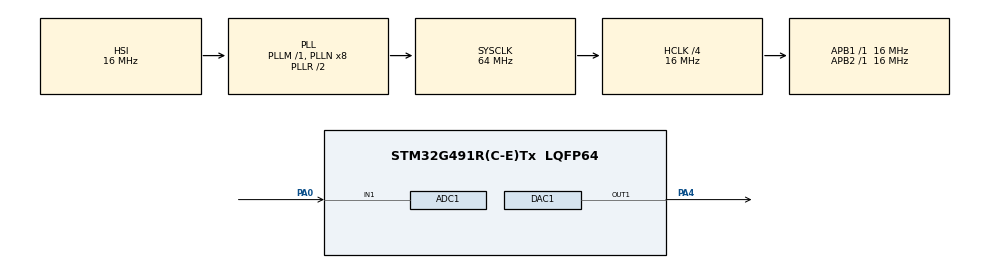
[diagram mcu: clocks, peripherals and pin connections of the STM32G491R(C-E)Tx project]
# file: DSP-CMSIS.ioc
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ADC1.Channel-0\#ChannelRegularConversion=ADC_CHANNEL_1
ADC1.NbrOfConversionFlag=1
ADC1.OffsetNumber-0\#ChannelRegularConversion=ADC_OFFSET_NONE
ADC1.Rank-0\#ChannelRegularConversion=1
ADC1.SamplingTime-0\#ChannelRegularConversion=ADC_SAMPLETIME_2CYCLES_5
ADC1.master=1
Mcu.Family=STM32G4
Mcu.Name=STM32G491R(C-E)Tx
Mcu.Package=LQFP64
NUCLEO-G491RE.BUTTON=1
NUCLEO-G491RE.LD2=true
NUCLEO-G491RE.VCP=true
NVIC.ADC1_2_IRQn=true\:0\:0\:false\:false\:true\:true\:true\:true
NVIC.EXTI15_10_IRQn=true\:0\:0\:false\:false\:true\:false\:true\:true
NVIC.PriorityGroup=NVIC_PRIORITYGROUP_4
NVIC.TIM2_IRQn=true\:0\:0\:false\:false\:true\:true\:true\:true
NVIC.TIM6_DAC_IRQn=true\:0\:0\:false\:false\:true\:true\:true\:true
PA0.Mode=IN1-Single-Ended
PA0.Signal=ADC1_IN1
PA13.GPIO_Label=T_SWDIO
PA13.Mode=Serial_Wire
PA13.Signal=SYS_JTMS-SWDIO
PA14.GPIO_Label=T_SWCLK
PA14.Mode=Serial_Wire
PA14.Signal=SYS_JTCK-SWCLK
PA2.Signal=LPUART1_TX
PA3.Signal=LPUART1_RX
PA4.Signal=COMP_DAC11_group
PB3.GPIO_Label=T_SWO
PB3.Signal=SYS_JTDO-SWO
PC14-OSC32_IN.GPIO_Label=RCC_OSC32_IN
PC14-OSC32_IN.Signal=RCC_OSC32_IN
PC15-OSC32_OUT.GPIO_Label=RCC_OSC32_OUT
PC15-OSC32_OUT.Signal=RCC_OSC32_OUT
PF0-OSC_IN.GPIO_Label=RCC_OSC_IN
PF0-OSC_IN.Signal=RCC_OSC_IN
PF1-OSC_OUT.GPIO_Label=RCC_OSC_OUT
PF1-OSC_OUT.Signal=RCC_OSC_OUT
ProjectManager.HeapSize=0x200
ProjectManager.StackSize=0x400
ProjectManager.TargetToolchain=STM32CubeIDE
RCC.ADC12Freq_Value=64000000
RCC.ADC345Freq_Value=64000000
RCC.AHBCLKDivider=RCC_SYSCLK_DIV4
RCC.AHBFreq_Value=16000000
RCC.APB1Freq_Value=16000000
RCC.APB1TimFreq_Value=16000000
RCC.APB2Freq_Value=16000000
RCC.APB2TimFreq_Value=16000000
RCC.CortexFreq_Value=16000000
RCC.EXTERNAL_CLOCK_VALUE=12288000
RCC.HCLKFreq_Value=16000000
RCC.HSE_VALUE=24000000
RCC.HSI48_VALUE=48000000
RCC.HSI_VALUE=16000000
RCC.LSE_VALUE=32768
RCC.RTCClockSelection=RCC_RTCCLKSOURCE_LSE
RCC.SYSCLKFreq_VALUE=64000000
RCC.SYSCLKSource=RCC_SYSCLKSOURCE_PLLCLK
RCC.USBFreq_Value=48000000
RCC.VCOOutputFreq_Value=128000000
SH.COMP_DAC11_group.0=DAC1_OUT1,DAC_OUT1
TIM2.PeriodNoDither=1
TIM2.Prescaler=999
VP_NUCLEO-G491RE_VS_BSP_COMMON.Mode=COMMON
VP_SYS_VS_DBSignals.Mode=DisableDeadBatterySignals
VP_TIM2_VS_ClockSourceINT.Mode=Internal
board=NUCLEO-G491RE

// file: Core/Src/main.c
/* USER CODE BEGIN Header */
/**
 ******************************************************************************
 * @file           : main.c
 * @brief          : Main program body
 ******************************************************************************
 * @attention
 *
 * Copyright (c) 2026 STMicroelectronics.
 * All rights reserved.
 *
 * This software is licensed under terms that can be found in the LICENSE file
 * in the root directory of this software component.
 * If no LICENSE file comes with this software, it is provided AS-IS.
 *
 ******************************************************************************
 */

/*
 *
 * 	El codigo esta preparado para aplicar filtros FIR en su version flotante o punto fijo
 * 	lo unico que debe hacerse es comentar aquello que no se va a usar (cosas de float si se quiere punto fijo y
 * 	al reves). Si se recorre el codigo vera que tiene comentarios cuando se esten inicializando las variables y funciones
 * 	de punto fijo o de punto flotante. Para que se vea mas claro, las cosas tipo q_X son de punto fijo y las de
 * 	floatX_t son de punto flotante
 *
 */

/* USER CODE END Header */
#include "main.h"
#include "adc.h"
#include "dac.h"
#include "tim.h"
#include "gpio.h"

/* USER CODE BEGIN Includes */

#include "FIR.h"
#include <math.h>
#include "arm_math.h"

/* USER CODE END Includes */

COM_InitTypeDef BspCOMInit;

/* USER CODE BEGIN PV */

/*
 *
 * Inicializo variables para CMSIS float
 *
 */

arm_fir_instance_f32 FIR; //Creo una instancia FIR float
float32_t Buffer_estado[N_FIR + 1]; //Por seguridad le doy +1

/*
 *
 * Inicializo variables para CMSIS Punto Fijo
 *
 */

//arm_fir_instance_q15 FIR; //Creo una instancia FIR Q15 (punto fijo)
//q15_t Buffer_estado[N_FIR + 2];
//q15_t coef[N_FIR + 1];

/*----------------------------*/

volatile uint8_t adc_ready = 0; //variable general.

/*
 *
 * 	Variables para FIR FLOAT
 *
 */
float32_t muestra = 0;

float32_t conv = 0;

/*
 *
 * 	Variables para FIR Punto fijo
 *
 */
//q15_t muestra = 0;
//q15_t conv = 0;

/* USER CODE END PV */

void SystemClock_Config(void);

int main(void) {

	/* USER CODE BEGIN 1 */

	//arm_float_to_q15(fir_pasabajo,coef,N_FIR + 1); //Convierto Coeficientes
	/* USER CODE END 1 */

	/* MCU Configuration--------------------------------------------------------*/

	/* Reset of all peripherals, Initializes the Flash interface and the Systick. */
	HAL_Init();

	/* Configure the system clock */
	SystemClock_Config();

	/* Initialize all configured peripherals */
	MX_GPIO_Init();
	MX_ADC1_Init();
	MX_DAC1_Init();
	MX_TIM2_Init();
	/* USER CODE BEGIN 2 */

	/*
	 *
	 * Inicializo el FIR FLOAT
	 *
	 *	Analizando los parametros en orden:
	 *	@&FIR, es el objeto tipo FIR creado
	 *	@N_FIR, es la cantidad de estados
	 *	@fir_pasabajo, son los coeficientes del filtro casteados a float32
	 *	@Buffer_estado, es el buffer (espacio de memoria) que le asigno para que trabaje el filtro
	 *	@1, es el tamaño del bloque que trabaja, lo pongo en 1 porque trabajamos muestra a muestra
	 */

	arm_fir_init_f32(&FIR, N_FIR + 1, (float32_t*)fir_pasabajo, Buffer_estado, 1);

	/*
	 *
	 * Inicializo el FIR Punto Fijo
	 *
	 *	Analizando los parametros en orden:
	 *	@&FIR, es el objeto tipo FIR creado
	 *	@N_FIR, es la cantidad de estados
	 *	@fir_pasabajo, son los coeficientes del filtro casteados a float32
	 *	@Buffer_estado, es el buffer (espacio de memoria) que le asigno para que trabaje el filtro
	 *	@1, es el tamaño del bloque que trabaja, lo pongo en 1 porque trabajamos muestra a muestra
	 */

	//arm_fir_init_q15(&FIR, N_FIR+1, coef, Buffer_estado, 1);
	/*------------------------------------------------------------------------------*/

	HAL_TIM_Base_Start_IT(&htim2);
	HAL_ADC_Start_IT(&hadc1);
	HAL_DAC_Start(&hdac1, DAC1_CHANNEL_1);

	/* USER CODE END 2 */

	/* Initialize led */
	BSP_LED_Init(LED_GREEN);

	/* Initialize USER push-button, will be used to trigger an interrupt each time it's pressed.*/
	BSP_PB_Init(BUTTON_USER, BUTTON_MODE_EXTI);

	/* Initialize COM1 port (115200, 8 bits (7-bit data + 1 stop bit), no parity */
	BspCOMInit.BaudRate = 115200;
	BspCOMInit.WordLength = COM_WORDLENGTH_8B;
	BspCOMInit.StopBits = COM_STOPBITS_1;
	BspCOMInit.Parity = COM_PARITY_NONE;
	BspCOMInit.HwFlowCtl = COM_HWCONTROL_NONE;
	if (BSP_COM_Init(COM1, &BspCOMInit) != BSP_ERROR_NONE) {
		Error_Handler();
	}

	/* Infinite loop */
	while (1) {

		/* USER CODE BEGIN 3 */

		if (adc_ready == 1) {

			/* --- FIR float --- */
			arm_fir_f32(&FIR, &muestra, &conv, 1);
			float32_t v = conv * 4095.0f / 3.3f;
			if (v < 0.0f)    v = 0.0f;
			if (v > 4095.0f) v = 4095.0f;

			/* --- FIR punto fijo --- */
			//arm_fir_q15(&FIR, &muestra, &conv, 1);
			//int32_t v = conv >> 3;
			//if (v < 0) v = 0;
			//if (v > 4095) v = 4095;

			HAL_DAC_SetValue(&hdac1, DAC_CHANNEL_1, DAC_ALIGN_12B_R, (uint32_t)v);
			adc_ready = 0;
		}

	}

	/* USER CODE END 3 */
}

void SystemClock_Config(void) {
	RCC_OscInitTypeDef RCC_OscInitStruct = { 0 };
	RCC_ClkInitTypeDef RCC_ClkInitStruct = { 0 };

	/** Configure the main internal regulator output voltage
	 */
	HAL_PWREx_ControlVoltageScaling(PWR_REGULATOR_VOLTAGE_SCALE1);

	/** Initializes the RCC Oscillators according to the specified parameters
	 * in the RCC_OscInitTypeDef structure.
	 */
	RCC_OscInitStruct.OscillatorType = RCC_OSCILLATORTYPE_HSI;
	RCC_OscInitStruct.HSIState = RCC_HSI_ON;
	RCC_OscInitStruct.HSICalibrationValue = RCC_HSICALIBRATION_DEFAULT;
	RCC_OscInitStruct.PLL.PLLState = RCC_PLL_ON;
	RCC_OscInitStruct.PLL.PLLSource = RCC_PLLSOURCE_HSI;
	RCC_OscInitStruct.PLL.PLLM = RCC_PLLM_DIV1;
	RCC_OscInitStruct.PLL.PLLN = 8;
	RCC_OscInitStruct.PLL.PLLP = RCC_PLLP_DIV2;
	RCC_OscInitStruct.PLL.PLLQ = RCC_PLLQ_DIV2;
	RCC_OscInitStruct.PLL.PLLR = RCC_PLLR_DIV2;
	if (HAL_RCC_OscConfig(&RCC_OscInitStruct) != HAL_OK) {
		Error_Handler();
	}

	/** Initializes the CPU, AHB and APB buses clocks
	 */
	RCC_ClkInitStruct.ClockType = RCC_CLOCKTYPE_HCLK | RCC_CLOCKTYPE_SYSCLK
			| RCC_CLOCKTYPE_PCLK1 | RCC_CLOCKTYPE_PCLK2;
	RCC_ClkInitStruct.SYSCLKSource = RCC_SYSCLKSOURCE_PLLCLK;
	RCC_ClkInitStruct.AHBCLKDivider = RCC_SYSCLK_DIV4;
	RCC_ClkInitStruct.APB1CLKDivider = RCC_HCLK_DIV1;
	RCC_ClkInitStruct.APB2CLKDivider = RCC_HCLK_DIV1;

	if (HAL_RCC_ClockConfig(&RCC_ClkInitStruct, FLASH_LATENCY_0) != HAL_OK) {
		Error_Handler();
	}
}

/* USER CODE BEGIN 4 */

void HAL_TIM_PeriodElapsedCallback(TIM_HandleTypeDef *htim) {

	if (htim->Instance == TIM2) {

		HAL_ADC_Start_IT(&hadc1);

	}

}

void HAL_ADC_ConvCpltCallback(ADC_HandleTypeDef *hadc) {

	if (hadc->Instance == ADC1) {

		/*
		 * 	Caso Punto Flotante
		 *
		 */

		muestra = HAL_ADC_GetValue(hadc) * 3.3f / 4095.0f; //es directamente la muestra la que nos llega
		adc_ready = 1;

		/*
		 *
		 * 	Caso Punto Fijo
		 *
		 */

		//muestra = (q15_t)(HAL_ADC_GetValue(hadc) << 3);   // 12 bits → rango 0..32760 de Q15
		//adc_ready = 1;
	}

}

/* USER CODE END 4 */

void Error_Handler(void) {
	__disable_irq();
	while (1) {
	}
}
